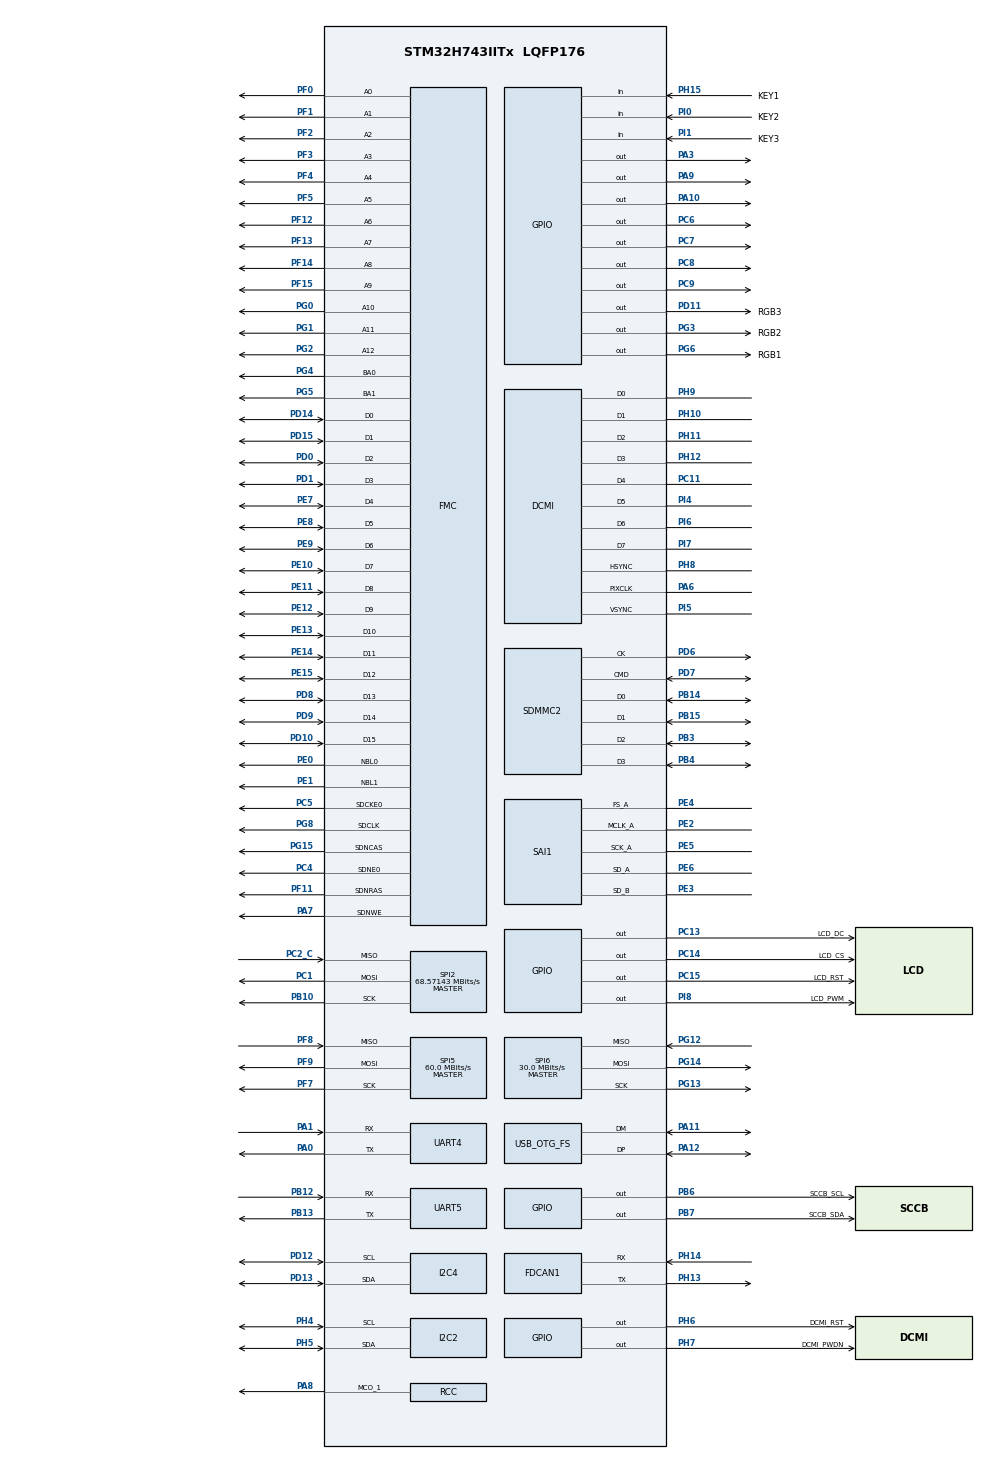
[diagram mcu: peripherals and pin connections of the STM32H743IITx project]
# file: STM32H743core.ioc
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CORTEX_M7.BaseAddress_Spec=0xC0000000
CORTEX_M7.CPU_DCache=Disabled
CORTEX_M7.CPU_ICache=Disabled
CORTEX_M7.Enable_S-Cortex_Memory_Protection_Unit_Region1_Settings_S=MPU_REGION_ENABLE
CORTEX_M7.Size_Spec=MPU_REGION_SIZE_32MB
CORTEX_M7.SubRegionDisable_Spec=0x0
CORTEX_M7.default_mode_Activation=0
DCMI.HSPolarity=DCMI_HSPOLARITY_LOW
DCMI.JPEGMode=DCMI_JPEG_ENABLE
DCMI.PCKPolarity=DCMI_PCKPOLARITY_RISING
DCMI.VSPolarity=DCMI_VSPOLARITY_LOW
Dma.DCMI.0.Direction=DMA_PERIPH_TO_MEMORY
Dma.DCMI.0.EventEnable=DISABLE
Dma.DCMI.0.FIFOMode=DMA_FIFOMODE_ENABLE
Dma.DCMI.0.FIFOThreshold=DMA_FIFO_THRESHOLD_HALFFULL
Dma.DCMI.0.Instance=DMA1_Stream0
Dma.DCMI.0.MemBurst=DMA_MBURST_SINGLE
Dma.DCMI.0.MemDataAlignment=DMA_MDATAALIGN_WORD
Dma.DCMI.0.MemInc=DMA_MINC_ENABLE
Dma.DCMI.0.Mode=DMA_CIRCULAR
Dma.DCMI.0.PeriphBurst=DMA_PBURST_SINGLE
Dma.DCMI.0.PeriphDataAlignment=DMA_PDATAALIGN_WORD
Dma.DCMI.0.PeriphInc=DMA_PINC_DISABLE
Dma.DCMI.0.Polarity=HAL_DMAMUX_REQ_GEN_RISING
Dma.DCMI.0.Priority=DMA_PRIORITY_VERY_HIGH
Dma.DCMI.0.RequestNumber=1
Dma.DCMI.0.SignalID=NONE
Dma.DCMI.0.SyncEnable=DISABLE
Dma.DCMI.0.SyncPolarity=HAL_DMAMUX_SYNC_NO_EVENT
Dma.DCMI.0.SyncRequestNumber=1
Dma.DCMI.0.SyncSignalID=NONE
Dma.MEMTOMEM.1.Direction=DMA_MEMORY_TO_MEMORY
Dma.MEMTOMEM.1.EventEnable=DISABLE
Dma.MEMTOMEM.1.FIFOMode=DMA_FIFOMODE_ENABLE
Dma.MEMTOMEM.1.FIFOThreshold=DMA_FIFO_THRESHOLD_HALFFULL
Dma.MEMTOMEM.1.Instance=DMA1_Stream1
Dma.MEMTOMEM.1.MemBurst=DMA_MBURST_SINGLE
Dma.MEMTOMEM.1.MemDataAlignment=DMA_MDATAALIGN_HALFWORD
Dma.MEMTOMEM.1.MemInc=DMA_MINC_ENABLE
Dma.MEMTOMEM.1.Mode=DMA_NORMAL
Dma.MEMTOMEM.1.PeriphBurst=DMA_PBURST_SINGLE
Dma.MEMTOMEM.1.PeriphDataAlignment=DMA_PDATAALIGN_HALFWORD
Dma.MEMTOMEM.1.PeriphInc=DMA_PINC_ENABLE
Dma.MEMTOMEM.1.Polarity=HAL_DMAMUX_REQ_GEN_RISING
Dma.MEMTOMEM.1.Priority=DMA_PRIORITY_HIGH
Dma.MEMTOMEM.1.RequestNumber=1
Dma.MEMTOMEM.1.SignalID=NONE
Dma.MEMTOMEM.1.SyncEnable=DISABLE
Dma.MEMTOMEM.1.SyncPolarity=HAL_DMAMUX_SYNC_NO_EVENT
Dma.MEMTOMEM.1.SyncRequestNumber=1
Dma.MEMTOMEM.1.SyncSignalID=NONE
Dma.Request0=DCMI
Dma.Request1=MEMTOMEM
FATFS._MAX_SS=4096
FDCAN1.CalculateBaudRateNominal=312500
FDCAN1.CalculateTimeBitNominal=3200
FDCAN1.CalculateTimeQuantumNominal=640.0
FMC.CASLatency1=FMC_SDRAM_CAS_LATENCY_3
FMC.ColumnBitsNumber1=FMC_SDRAM_COLUMN_BITS_NUM_9
FMC.ExitSelfRefreshDelay1=6
FMC.LoadToActiveDelay1=2
FMC.RCDDelay1=2
FMC.RPDelay1=2
FMC.ReadBurst1=FMC_SDRAM_RBURST_ENABLE
FMC.ReadPipeDelay1=FMC_SDRAM_RPIPE_DELAY_1
FMC.RowCycleDelay1=6
FMC.SDClockPeriod1=FMC_SDRAM_CLOCK_PERIOD_2
FMC.SelfRefreshTime1=4
FMC.WriteRecoveryTime1=3
I2C2.Timing=0x307075B1
I2C4.Timing=0x307075B1
Mcu.Family=STM32H7
Mcu.Name=STM32H743IITx
Mcu.Package=LQFP176
NVIC.DCMI_IRQn=true\:0\:0\:false\:false\:true\:true\:true\:true
NVIC.DMA1_Stream0_IRQn=true\:1\:0\:true\:false\:true\:false\:true\:true
NVIC.OTG_FS_IRQn=true\:0\:0\:false\:false\:true\:false\:true\:true
NVIC.PriorityGroup=NVIC_PRIORITYGROUP_4
NVIC.SPI6_IRQn=true\:3\:0\:true\:false\:true\:true\:true\:true
NVIC.TIM3_IRQn=true\:4\:0\:true\:false\:true\:true\:true\:true
PA0.Mode=Asynchronous
PA0.Signal=UART4_TX
PA1.Mode=Asynchronous
PA1.Signal=UART4_RX
PA10.Signal=GPIO_Output
PA11.Mode=Device_Only
PA11.Signal=USB_OTG_FS_DM
PA12.Mode=Device_Only
PA12.Signal=USB_OTG_FS_DP
PA13\ (JTMS/SWDIO).Mode=Serial_Wire
PA13\ (JTMS/SWDIO).Signal=DEBUG_JTMS-SWDIO
PA14\ (JTCK/SWCLK).Mode=Serial_Wire
PA14\ (JTCK/SWCLK).Signal=DEBUG_JTCK-SWCLK
PA3.Signal=GPIO_Output
PA6.Mode=Slave_8_bits_External_Synchro
PA6.Signal=DCMI_PIXCLK
PA7.Signal=FMC_SDNWE
PA8.Mode=Clock-out-1
PA8.Signal=RCC_MCO_1
PA9.Signal=GPIO_Output
PB10.Mode=Full_Duplex_Master
PB10.Signal=SPI2_SCK
PB12.Mode=Asynchronous
PB12.Signal=UART5_RX
PB13.Mode=Asynchronous
PB13.Signal=UART5_TX
PB14.Mode=SD_4_bits_Wide_bus
PB14.Signal=SDMMC2_D0
PB15.Mode=SD_4_bits_Wide_bus
PB15.Signal=SDMMC2_D1
PB3\ (JTDO/TRACESWO).Mode=SD_4_bits_Wide_bus
PB3\ (JTDO/TRACESWO).Signal=SDMMC2_D2
PB4\ (NJTRST).Mode=SD_4_bits_Wide_bus
PB4\ (NJTRST).Signal=SDMMC2_D3
PB6.GPIO_Label=SCCB_SCL
PB6.Signal=GPIO_Output
PB7.GPIO_Label=SCCB_SDA
PB7.Signal=GPIO_Output
PC1.Mode=Full_Duplex_Master
PC1.Signal=SPI2_MOSI
PC11.Mode=Slave_8_bits_External_Synchro
PC11.Signal=DCMI_D4
PC13.GPIO_Label=LCD_DC
PC13.Signal=GPIO_Output
PC14-OSC32_IN\ (OSC32_IN).GPIO_Label=LCD_CS
PC14-OSC32_IN\ (OSC32_IN).Signal=GPIO_Output
PC15-OSC32_OUT\ (OSC32_OUT).GPIO_Label=LCD_RST
PC15-OSC32_OUT\ (OSC32_OUT).Signal=GPIO_Output
PC2_C.Mode=Full_Duplex_Master
PC2_C.Signal=SPI2_MISO
PC4.Mode=SdramChipSelect1_1
PC4.Signal=FMC_SDNE0
PC5.Mode=SdramChipSelect1_1
PC5.Signal=FMC_SDCKE0
PC6.Signal=GPIO_Output
PC7.Signal=GPIO_Output
PC8.Signal=GPIO_Output
PC9.Signal=GPIO_Output
PD0.Signal=FMC_D2_DA2
PD1.Signal=FMC_D3_DA3
PD10.Signal=FMC_D15_DA15
PD11.GPIO_Label=RGB3
PD11.Signal=GPIO_Output
PD12.Mode=I2C
PD12.Signal=I2C4_SCL
PD13.Mode=I2C
PD13.Signal=I2C4_SDA
PD14.Signal=FMC_D0_DA0
PD15.Signal=FMC_D1_DA1
PD6.Mode=SD_4_bits_Wide_bus
PD6.Signal=SDMMC2_CK
PD7.Mode=SD_4_bits_Wide_bus
PD7.Signal=SDMMC2_CMD
PD8.Signal=FMC_D13_DA13
PD9.Signal=FMC_D14_DA14
PE0.Signal=FMC_NBL0
PE1.Signal=FMC_NBL1
PE10.Signal=FMC_D7_DA7
PE11.Signal=FMC_D8_DA8
PE12.Signal=FMC_D9_DA9
PE13.Signal=FMC_D10_DA10
PE14.Signal=FMC_D11_DA11
PE15.Signal=FMC_D12_DA12
PE2.Mode=SAI_A_MasterWithClock
PE2.Signal=SAI1_MCLK_A
PE3.Mode=SAI_B_SyncSlave
PE3.Signal=SAI1_SD_B
PE4.Mode=SAI_A_MasterWithClock
PE4.Signal=SAI1_FS_A
PE5.Mode=SAI_A_MasterWithClock
PE5.Signal=SAI1_SCK_A
PE6.Mode=SAI_A_MasterWithClock
PE6.Signal=SAI1_SD_A
PE7.Signal=FMC_D4_DA4
PE8.Signal=FMC_D5_DA5
PE9.Signal=FMC_D6_DA6
PF0.Signal=FMC_A0
PF1.Signal=FMC_A1
PF11.Signal=FMC_SDNRAS
PF12.Signal=FMC_A6
PF13.Signal=FMC_A7
PF14.Signal=FMC_A8
PF15.Signal=FMC_A9
PF2.Signal=FMC_A2
PF3.Signal=FMC_A3
PF4.Signal=FMC_A4
PF5.Signal=FMC_A5
PF7.Mode=Full_Duplex_Master
PF7.Signal=SPI5_SCK
PF8.Mode=Full_Duplex_Master
PF8.Signal=SPI5_MISO
PF9.Mode=Full_Duplex_Master
PF9.Signal=SPI5_MOSI
PG0.Signal=FMC_A10
PG1.Signal=FMC_A11
PG12.Mode=Full_Duplex_Master
PG12.Signal=SPI6_MISO
PG13.Mode=Full_Duplex_Master
PG13.Signal=SPI6_SCK
PG14.Mode=Full_Duplex_Master
PG14.Signal=SPI6_MOSI
PG15.Signal=FMC_SDNCAS
PG2.Signal=FMC_A12
PG3.GPIO_Label=RGB2
PG3.Signal=GPIO_Output
PG4.Signal=FMC_A14_BA0
PG5.Signal=FMC_A15_BA1
PG6.GPIO_Label=RGB1
PG6.Signal=GPIO_Output
PG8.Signal=FMC_SDCLK
PH0-OSC_IN\ (PH0).Mode=HSE-External-Clock-Source
PH0-OSC_IN\ (PH0).Signal=RCC_OSC_IN
PH10.Mode=Slave_8_bits_External_Synchro
PH10.Signal=DCMI_D1
PH11.Mode=Slave_8_bits_External_Synchro
PH11.Signal=DCMI_D2
PH12.Mode=Slave_8_bits_External_Synchro
PH12.Signal=DCMI_D3
PH13.Mode=FDCAN_Activate
PH13.Signal=FDCAN1_TX
PH14.Mode=FDCAN_Activate
PH14.Signal=FDCAN1_RX
PH15.GPIO_Label=KEY1
PH15.Signal=GPIO_Input
PH4.Mode=I2C
PH4.Signal=I2C2_SCL
PH5.Mode=I2C
PH5.Signal=I2C2_SDA
PH6.GPIO_Label=DCMI_RST
PH6.Signal=GPIO_Output
PH7.GPIO_Label=DCMI_PWDN
PH7.Signal=GPIO_Output
PH8.Mode=Slave_8_bits_External_Synchro
PH8.Signal=DCMI_HSYNC
PH9.Mode=Slave_8_bits_External_Synchro
PH9.Signal=DCMI_D0
PI0.GPIO_Label=KEY2
PI0.Signal=GPIO_Input
PI1.GPIO_Label=KEY3
PI1.Signal=GPIO_Input
PI4.Mode=Slave_8_bits_External_Synchro
PI4.Signal=DCMI_D5
PI5.Mode=Slave_8_bits_External_Synchro
PI5.Signal=DCMI_VSYNC
PI6.Mode=Slave_8_bits_External_Synchro
PI6.Signal=DCMI_D6
PI7.Mode=Slave_8_bits_External_Synchro
PI7.Signal=DCMI_D7
PI8.GPIO_Label=LCD_PWM
PI8.Signal=GPIO_Output
ProjectManager.HeapSize=0x1000
ProjectManager.StackSize=0x2000
ProjectManager.TargetToolchain=MDK-ARM V5.32
RCC.ADCFreq_Value=75000000
RCC.APB1Freq_Value=120000000
RCC.APB2Freq_Value=120000000
RCC.APB3Freq_Value=120000000
RCC.APB4Freq_Value=120000000
RCC.CortexFreq_Value=480000000
RCC.D1PPRE=RCC_APB3_DIV2
RCC.D2PPRE1=RCC_APB1_DIV2
RCC.D2PPRE2=RCC_APB2_DIV2
RCC.D3PPRE=RCC_APB4_DIV2
RCC.DIVM1=5
RCC.DIVM2=2
RCC.DIVM3=20
RCC.DIVN1=192
RCC.DIVN2=12
RCC.DIVQ1=7
RCC.DIVR1=4
RCC.FDCANCLockSelection=RCC_FDCANCLKSOURCE_HSE
RCC.HCLKFreq_Value=240000000
RCC.HPRE=RCC_HCLK_DIV2
RCC.HSE_VALUE=25000000
RCC.PLL2FRACN=0
RCC.PLL3FRACN=0
RCC.PLLFRACN=0
RCC.PLLSourceVirtual=RCC_PLLSOURCE_HSE
RCC.PWR_Regulator_Voltage_Scale=PWR_REGULATOR_VOLTAGE_SCALE0
RCC.ProductRev=revV
RCC.RCC_TIM_PRescaler_Selection=RCC_TIMPRES_ACTIVATED
RCC.SDMMC1CLockSelection=RCC_SDMMCCLKSOURCE_PLL2
RCC.SYSCLKFreq_VALUE=480000000
RCC.SYSCLKSource=RCC_SYSCLKSOURCE_PLLCLK
RCC.USBCLockSelection=RCC_USBCLKSOURCE_HSI48
RCC.USBFreq_Value=48000000
SAI1.ErrorAudioFreq-SAI_A_MasterWithClock=39.5 %
SAI1.Instance-SAI_A_MasterWithClock=SAI$Index_Block_A
SAI1.Instance-SAI_B_SyncSlave=SAI$Index_Block_B
SAI1.MClockEnable-SAI_A_MasterWithClock=SAI_MASTERCLOCK_ENABLE
SAI1.RealAudioFreq-SAI_A_MasterWithClock=267.857 KHz
SAI1.VirtualMode-SAI_A_MasterWithClock=VM_MASTER
SAI1.VirtualMode-SAI_B_SyncSlave=VM_SLAVE
SDMMC2.HardwareFlowControl=SDMMC_HARDWARE_FLOW_CONTROL_ENABLE
SH.FMC_A0.0=FMC_A0,13b-sda1
SH.FMC_A1.0=FMC_A1,13b-sda1
SH.FMC_A10.0=FMC_A10,13b-sda1
SH.FMC_A11.0=FMC_A11,13b-sda1
SH.FMC_A12.0=FMC_A12,13b-sda1
SH.FMC_A14_BA0.0=FMC_BA0,FourSdramBanks1
SH.FMC_A15_BA1.0=FMC_BA1,FourSdramBanks1
SH.FMC_A2.0=FMC_A2,13b-sda1
SH.FMC_A3.0=FMC_A3,13b-sda1
SH.FMC_A4.0=FMC_A4,13b-sda1
SH.FMC_A5.0=FMC_A5,13b-sda1
SH.FMC_A6.0=FMC_A6,13b-sda1
SH.FMC_A7.0=FMC_A7,13b-sda1
SH.FMC_A8.0=FMC_A8,13b-sda1
SH.FMC_A9.0=FMC_A9,13b-sda1
SH.FMC_D0_DA0.0=FMC_D0,sd-16b-d1
SH.FMC_D10_DA10.0=FMC_D10,sd-16b-d1
SH.FMC_D11_DA11.0=FMC_D11,sd-16b-d1
SH.FMC_D12_DA12.0=FMC_D12,sd-16b-d1
SH.FMC_D13_DA13.0=FMC_D13,sd-16b-d1
SH.FMC_D14_DA14.0=FMC_D14,sd-16b-d1
SH.FMC_D15_DA15.0=FMC_D15,sd-16b-d1
SH.FMC_D1_DA1.0=FMC_D1,sd-16b-d1
SH.FMC_D2_DA2.0=FMC_D2,sd-16b-d1
SH.FMC_D3_DA3.0=FMC_D3,sd-16b-d1
SH.FMC_D4_DA4.0=FMC_D4,sd-16b-d1
SH.FMC_D5_DA5.0=FMC_D5,sd-16b-d1
SH.FMC_D6_DA6.0=FMC_D6,sd-16b-d1
SH.FMC_D7_DA7.0=FMC_D7,sd-16b-d1
SH.FMC_D8_DA8.0=FMC_D8,sd-16b-d1
SH.FMC_D9_DA9.0=FMC_D9,sd-16b-d1
SH.FMC_NBL0.0=FMC_NBL0,Sd2ByteEnable1
SH.FMC_NBL1.0=FMC_NBL1,Sd2ByteEnable1
SH.FMC_SDCLK.0=FMC_SDCLK,13b-sda1
SH.FMC_SDNCAS.0=FMC_SDNCAS,13b-sda1
SH.FMC_SDNRAS.0=FMC_SDNRAS,13b-sda1
SH.FMC_SDNWE.0=FMC_SDNWE,13b-sda1
SPI2.CalculateBaudRate=68.57143 MBits/s
SPI2.Direction=SPI_DIRECTION_2LINES
SPI2.Mode=SPI_MODE_MASTER
SPI2.VirtualType=VM_MASTER
SPI5.CalculateBaudRate=60.0 MBits/s
SPI5.Direction=SPI_DIRECTION_2LINES
SPI5.Mode=SPI_MODE_MASTER
SPI5.VirtualType=VM_MASTER
SPI6.BaudRatePrescaler=SPI_BAUDRATEPRESCALER_4
SPI6.CLKPhase=SPI_PHASE_1EDGE
SPI6.CLKPolarity=SPI_POLARITY_HIGH
SPI6.CalculateBaudRate=30.0 MBits/s
SPI6.DataSize=SPI_DATASIZE_8BIT
SPI6.Direction=SPI_DIRECTION_2LINES
SPI6.Mode=SPI_MODE_MASTER
SPI6.VirtualType=VM_MASTER
TIM3.AutoReloadPreload=TIM_AUTORELOAD_PRELOAD_ENABLE
TIM3.Period=24000
TIM3.Prescaler=10000
TIM6.AutoReloadPreload=TIM_AUTORELOAD_PRELOAD_ENABLE
TIM6.Period=24000-1
TIM6.Prescaler=0
USB_DEVICE.CLASS_NAME_FS=CDC
USB_DEVICE.VirtualMode-CDC_FS=Cdc
USB_DEVICE.VirtualModeFS=Cdc_FS
USB_OTG_FS.VirtualMode=Device_Only
VP_FATFS_VS_SDIO.Mode=SDIO
VP_TIM3_VS_ClockSourceINT.Mode=Internal
VP_TIM6_VS_ClockSourceINT.Mode=Enable_Timer
VP_USB_DEVICE_VS_USB_DEVICE_CDC_FS.Mode=CDC_FS
board=custom

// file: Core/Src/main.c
/* USER CODE BEGIN Header */
/**
  ******************************************************************************
  * @file           : main.c
  * @brief          : Main program body
  ******************************************************************************
  * @attention
  *
  * Copyright (c) 2024 STMicroelectronics.
  * All rights reserved.
  *
  * This software is licensed under terms that can be found in the LICENSE file
  * in the root directory of this software component.
  * If no LICENSE file comes with this software, it is provided AS-IS.
  *
  ******************************************************************************
  */
/* USER CODE END Header */
#include "main.h"
#include "dcmi.h"
#include "dma.h"
#include "fatfs.h"
#include "fdcan.h"
#include "i2c.h"
#include "sai.h"
#include "sdmmc.h"
#include "spi.h"
#include "tim.h"
#include "usart.h"
#include "usb_device.h"
#include "gpio.h"
#include "fmc.h"

/* USER CODE BEGIN PTD */
uint16_t LCD_RAM[28900]__attribute__((section(".bss.ARM.__at_0XC0000000")));

uint8_t LCD_RAM1[57800]__attribute__((section(".bss.ARM.__at_0XC000E200")));
//uint32_t jpeg_data_buf[30][30] __attribute__((section(".bss.ARM.__at_0XC0000000")));//SDRAM中的数据
/* USER CODE END PTD */

/* USER CODE BEGIN PM */
extern uint8_t CDC_Transmit_FS(uint8_t* Buf, uint16_t Len);
struct send_data my_data;
 bool usb_data_flag=0;
/* USER CODE END PM */

void SystemClock_Config(void);
void PeriphCommonClock_Config(void);

/* USER CODE BEGIN 0 */
uint8_t show_frames=0;
void HAL_TIM_PeriodElapsedCallback(TIM_HandleTypeDef *htim)//
{
	if(htim == &htim3)  //判断中断是否来自于定时器1
   {

		__HAL_TIM_CLEAR_IT(&htim3, TIM_IT_UPDATE);
		 show_frames=1;
   }

}

void HAL_DCMI_FrameEventCallback(DCMI_HandleTypeDef *hdcmi)
{

		LCD_ShowPicture(0,0,170,170,(uint8_t *)LCD_RAM);

		__HAL_DCMI_ENABLE_IT(hdcmi,DCMI_IT_FRAME);

}
void DMA1_Stream1_IRQHandler(void)
{
//	for(int i=0;i<8;i++)
//	{
//		my_data.DATA[i]=LCD_RAM[i];
//
//	}
//	CDC_Transmit_FS((uint8_t*)&my_data, sizeof(my_data));

}

/* USER CODE END 0 */

int main(void)
{
  /* USER CODE BEGIN 1 */

	uint16_t cnmd[8]={0x01,0x02,0x03,0x04,0x1234,0x4567,0x7777,0x1235};
  /* USER CODE END 1 */

  /* MCU Configuration--------------------------------------------------------*/

  /* Reset of all peripherals, Initializes the Flash interface and the Systick. */
  HAL_Init();

  /* USER CODE BEGIN Init */
    my_data.tail[0]=0x00;
		my_data.tail[1]=0x00;
		my_data.tail[2]=0x80;
		my_data.tail[3]=0x7F;
  /* USER CODE END Init */

  /* Configure the system clock */
  SystemClock_Config();

/* Configure the peripherals common clocks */
  PeriphCommonClock_Config();

  /* Initialize all configured peripherals */
  MX_GPIO_Init();
  MX_DMA_Init();
  MX_FMC_Init();
  MX_FDCAN1_Init();
  MX_I2C2_Init();
  MX_SAI1_Init();
  MX_SDMMC2_SD_Init();
  MX_SPI5_Init();
  MX_UART5_Init();
  MX_UART4_Init();
  MX_SPI6_Init();
  MX_SPI2_Init();
  MX_TIM3_Init();
  MX_TIM6_Init();
  MX_USB_DEVICE_Init();
  MX_DCMI_Init();
  MX_I2C4_Init();
  MX_FATFS_Init();
  /* USER CODE BEGIN 2 */

  __HAL_TIM_CLEAR_IT(&htim3, TIM_IT_UPDATE);
	HAL_TIM_Base_Start_IT(&htim3);
	HAL_TIM_Base_Start_IT(&htim6);
	RCC->CFGR|=2<<22;//开启时钟引脚PA7输出HSE外部高速时钟 25MHZ
	LCD_Init();
	LCD_Fill(0,0,320,172,BLUE);//0XF800,0X7E0
	ov5640_Init();

	SDRAM_initialization_sequence();//SDRAM初始化序列
	HAL_SDRAM_ProgramRefreshRate(&hsdram1,1500);//隔1880个计数值进行刷新SDRAM，防止SDRAM数据丢失

	__HAL_DCMI_ENABLE_IT(&hdcmi, DCMI_IT_FRAME);
	 DCMI->CR |=DCMI_CR_CAPTURE;

	 HAL_DCMI_Start_DMA(&hdcmi,DCMI_MODE_CONTINUOUS,(uint32_t)LCD_RAM,14450);
//	uint16_t sdram_data;
//	*(__IO uint16_t *)(SDRAM_BASE_ADDR + 0x100) = 399;
//	sdram_data = *(uint16_t *)(SDRAM_BASE_ADDR + 0x100) ;

	//LCD_ShowIntNum(10,10,(uint16_t)dcmi_line_buf[0][0],6,WHITE,BLACK,32);

	uint8_t isopen=f_open(&SDFile,"cnmd.txt",FA_READ);
	if(isopen==0)
	{
			char buf[10];

			uint32_t br;
			if(f_read(&SDFile,buf,10,&br)==0)
			{
			//	LCD_ShowIntNum(10,80,buf[0] ,6,WHITE,BLACK,32);
			}
	}

  /* USER CODE END 2 */

  /* Infinite loop */
  while (1)
  {

  }
}

void SystemClock_Config(void)
{
  RCC_OscInitTypeDef RCC_OscInitStruct = {0};
  RCC_ClkInitTypeDef RCC_ClkInitStruct = {0};

  /** Supply configuration update enable
  */
  HAL_PWREx_ConfigSupply(PWR_LDO_SUPPLY);

  /** Configure the main internal regulator output voltage
  */
  __HAL_PWR_VOLTAGESCALING_CONFIG(PWR_REGULATOR_VOLTAGE_SCALE1);

  while(!__HAL_PWR_GET_FLAG(PWR_FLAG_VOSRDY)) {}

  __HAL_RCC_SYSCFG_CLK_ENABLE();
  __HAL_PWR_VOLTAGESCALING_CONFIG(PWR_REGULATOR_VOLTAGE_SCALE0);

  while(!__HAL_PWR_GET_FLAG(PWR_FLAG_VOSRDY)) {}

  /** Initializes the RCC Oscillators according to the specified parameters
  * in the RCC_OscInitTypeDef structure.
  */
  RCC_OscInitStruct.OscillatorType = RCC_OSCILLATORTYPE_HSI48|RCC_OSCILLATORTYPE_HSI
                              |RCC_OSCILLATORTYPE_HSE;
  RCC_OscInitStruct.HSEState = RCC_HSE_BYPASS;
  RCC_OscInitStruct.HSIState = RCC_HSI_DIV1;
  RCC_OscInitStruct.HSICalibrationValue = RCC_HSICALIBRATION_DEFAULT;
  RCC_OscInitStruct.HSI48State = RCC_HSI48_ON;
  RCC_OscInitStruct.PLL.PLLState = RCC_PLL_ON;
  RCC_OscInitStruct.PLL.PLLSource = RCC_PLLSOURCE_HSE;
  RCC_OscInitStruct.PLL.PLLM = 5;
  RCC_OscInitStruct.PLL.PLLN = 192;
  RCC_OscInitStruct.PLL.PLLP = 2;
  RCC_OscInitStruct.PLL.PLLQ = 7;
  RCC_OscInitStruct.PLL.PLLR = 4;
  RCC_OscInitStruct.PLL.PLLRGE = RCC_PLL1VCIRANGE_2;
  RCC_OscInitStruct.PLL.PLLVCOSEL = RCC_PLL1VCOWIDE;
  RCC_OscInitStruct.PLL.PLLFRACN = 0;
  if (HAL_RCC_OscConfig(&RCC_OscInitStruct) != HAL_OK)
  {
    Error_Handler();
  }

  /** Initializes the CPU, AHB and APB buses clocks
  */
  RCC_ClkInitStruct.ClockType = RCC_CLOCKTYPE_HCLK|RCC_CLOCKTYPE_SYSCLK
                              |RCC_CLOCKTYPE_PCLK1|RCC_CLOCKTYPE_PCLK2
                              |RCC_CLOCKTYPE_D3PCLK1|RCC_CLOCKTYPE_D1PCLK1;
  RCC_ClkInitStruct.SYSCLKSource = RCC_SYSCLKSOURCE_PLLCLK;
  RCC_ClkInitStruct.SYSCLKDivider = RCC_SYSCLK_DIV1;
  RCC_ClkInitStruct.AHBCLKDivider = RCC_HCLK_DIV2;
  RCC_ClkInitStruct.APB3CLKDivider = RCC_APB3_DIV2;
  RCC_ClkInitStruct.APB1CLKDivider = RCC_APB1_DIV2;
  RCC_ClkInitStruct.APB2CLKDivider = RCC_APB2_DIV2;
  RCC_ClkInitStruct.APB4CLKDivider = RCC_APB4_DIV2;

  if (HAL_RCC_ClockConfig(&RCC_ClkInitStruct, FLASH_LATENCY_4) != HAL_OK)
  {
    Error_Handler();
  }
  HAL_RCC_MCOConfig(RCC_MCO1, RCC_MCO1SOURCE_HSI, RCC_MCODIV_1);
}

void PeriphCommonClock_Config(void)
{
  RCC_PeriphCLKInitTypeDef PeriphClkInitStruct = {0};

  /** Initializes the peripherals clock
  */
  PeriphClkInitStruct.PeriphClockSelection = RCC_PERIPHCLK_TIM;
  PeriphClkInitStruct.TIMPresSelection = RCC_TIMPRES_ACTIVATED;

  if (HAL_RCCEx_PeriphCLKConfig(&PeriphClkInitStruct) != HAL_OK)
  {
    Error_Handler();
  }
}

void Error_Handler(void)
{
  __disable_irq();
  while (1)
  {
  }
}
